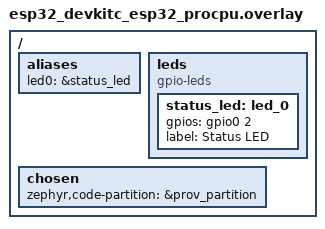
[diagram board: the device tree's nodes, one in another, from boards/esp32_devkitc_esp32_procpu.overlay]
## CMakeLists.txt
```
# SPDX-License-Identifier: Apache-2.0
#
# Wi-Fi provisioner: Improv Wi-Fi over BLE in its own image, launched by
# MCUboot from prov_partition. Built as an extra sysbuild image by each app's
# sysbuild.cmake (see sysbuild/provisioning.cmake); not built on its own.
cmake_minimum_required(VERSION 3.20.0)

list(APPEND ZEPHYR_EXTRA_MODULES
  ${CMAKE_CURRENT_SOURCE_DIR}/../../lib/common
)

find_package(Zephyr REQUIRED HINTS $ENV{ZEPHYR_BASE})
project(wifi_provisioner C)

target_sources(app PRIVATE src/main.c)
# Exactly one provisioning protocol (the APP_PROV_PROTOCOL choice).
if(CONFIG_APP_WIFI_PROV_SOFTAP)
  target_sources(app PRIVATE src/softap.c)
elseif(CONFIG_APP_PROV_ZTP)
  target_sources(app PRIVATE
    src/ztp.c
    src/ztp_envelope.c
    src/ztp_manifest.c
    src/ztp_apply.c
  )
else()
  target_sources(app PRIVATE src/improv.c)
endif()
target_sources_ifdef(CONFIG_APP_PROV_ZTP_CRYPTO app PRIVATE src/ztp_crypto.c)
target_sources_ifdef(CONFIG_APP_PROV_ZTP_CRYPTO_SELFTEST app PRIVATE src/ztp_selftest.c)
```

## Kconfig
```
# SPDX-License-Identifier: Apache-2.0
#
# Wi-Fi provisioner. Shared options come from the lib/common module.

mainmenu "Wi-Fi Provisioner"

menu "Wi-Fi provisioner"

config APP_WIFI_PROV_WINDOW_S
	int "Provisioning window (s)"
	default 900
	range 30 86400
	help
	  How long the provisioner advertises. When it expires and the
	  application still has credentials (entered with the button pattern),
	  it reboots back into the application; with no credentials it stops
	  advertising until sw0 is pressed.

config APP_WIFI_PROV_CONNECT_TIMEOUT_S
	int "Seconds to wait for an IPv4 address when testing credentials"
	default 30
	range 5 120

choice APP_PROV_PROTOCOL
	prompt "Provisioning protocol"
	default APP_PROV_IMPROV
	help
	  Exactly one protocol per image. Two 128-bit service UUIDs do not fit
	  one 31-byte advertising PDU, so a second BLE service would be
	  invisible to any client that scans by UUID; and the prov partition
	  has no room for both.

config APP_PROV_IMPROV
	bool "Improv Wi-Fi over BLE"
	help
	  Wi-Fi SSID and password only, from any stock Improv client.

config APP_PROV_ZTP
	bool "lab-ztp-provisioner over BLE (Wi-Fi and Cumulocity)"
	select APP_PROV_ZTP_CRYPTO
	help
	  The device is a peripheral for a lab-ztp-provisioner relay (the web
	  or desktop app on a phone or laptop), which forwards its signed
	  enrollment request to a ZTP server and writes the server's bundle
	  back. One session delivers Wi-Fi credentials and Cumulocity
	  onboarding: tenant, external ID and a one-time password the server
	  has already registered. The server profile must select
	  `crypto: {suite: p256}`.

config APP_WIFI_PROV_SOFTAP
	bool "SoftAP captive portal (spike)"
	depends on ESP32_WIFI_AP_STA_MODE
	help
	  c8y-direct-spikes, Spike E: an open access point "<hostname>-setup"
	  with DHCP, a catch-all DNS responder and an HTTP form, instead of
	  a BLE service. Use overlay-softap.conf and softap.overlay.

endchoice

config APP_WIFI_PROV_REQUIRE_AUTH
	bool "Require a sw0 press to authorize provisioning"
	depends on APP_PROV_IMPROV
	help
	  Start in the Improv "authorization required" state and refuse Wi-Fi
	  settings until sw0 is pressed on the device, which authorizes for 60 s.
	  Proves physical presence, since the link is not encrypted.

config APP_PROV_ZTP_CRYPTO
	bool
	help
	  The p256 crypto suite of the lab-ztp-provisioner protocol (ECDSA
	  P-256 / SHA-256 signatures; P-256 ECDH + HKDF-SHA256 +
	  ChaCha20-Poly1305 sealing), all over PSA. One curve only: Mbed TLS
	  has no Ed25519, and the prov partition has no room for a second.
	select MBEDTLS
	select MBEDTLS_PSA_CRYPTO_C
	select PSA_WANT_ECC_SECP_R1_256
	select PSA_WANT_KEY_TYPE_ECC_KEY_PAIR_BASIC
	select PSA_WANT_KEY_TYPE_ECC_KEY_PAIR_GENERATE
	select PSA_WANT_KEY_TYPE_ECC_KEY_PAIR_IMPORT
	select PSA_WANT_KEY_TYPE_ECC_KEY_PAIR_EXPORT
	select PSA_WANT_KEY_TYPE_ECC_PUBLIC_KEY
	select PSA_WANT_ALG_ECDSA
	select PSA_WANT_ALG_SHA_256
	select PSA_WANT_ALG_ECDH
	select PSA_WANT_ALG_HKDF
	select PSA_WANT_KEY_TYPE_DERIVE
	select PSA_WANT_KEY_TYPE_CHACHA20
	select PSA_WANT_ALG_CHACHA20_POLY1305
	# The identity key persists in PSA ITS; the board conf picks the
	# settings-backed ITS store, as the tedge profiles do.
	select SECURE_STORAGE
	select SETTINGS
	select BASE64

config APP_PROV_ZTP_PSA_KEY_ID
	hex "PSA key ID of the ZTP identity key"
	depends on APP_PROV_ZTP_CRYPTO
	default 0x0007E572
	range 0x00000001 0x3FFFFFFF
	help
	  Persistent key ID in PSA ITS. Distinct from CONFIG_TEDGE_PSA_KEY_ID
	  (the Cumulocity device key, 0x0007E571 by default): the two answer
	  to different trust roots, and re-provisioning must not replace the
	  key the device holds a Cumulocity certificate for.

if APP_PROV_ZTP

config APP_PROV_ZTP_RX_BYTES
	int "Largest server response the device accepts (bytes)"
	default 4096
	range 1024 16384
	help
	  Size of the buffer the relay writes the server's response into. The
	  device sends it to the server as max_response_bytes, so a bundle that
	  would not fit comes back as a rejection with a reason instead of a
	  truncated write. A Wi-Fi + Cumulocity bundle is about 2.5 KB.

config APP_PROV_ZTP_SERVER_PUBKEY
	string "Pinned ZTP server public key (base64, P-256)"
	default ""
	help
	  Reserved for verifying the server's signature on the bundle. Empty
	  (the only supported value for now) means trust on first use: the
	  bundle is applied unverified, with a warning. The sealed Cumulocity
	  token is protected either way; what TOFU leaves open is a hostile
	  relay choosing the Wi-Fi network and the tenant.

endif # APP_PROV_ZTP

config APP_PROV_ZTP_CRYPTO_SELFTEST
	bool "Run the ZTP p256 crypto self-test at boot"
	select APP_PROV_ZTP_CRYPTO
	help
	  Before provisioning starts, check every PSA operation the ZTP p256
	  suite needs against reference vectors from the lab-ztp-provisioner
	  Go implementation, and log PASS/FAIL with timings. For bring-up and
	  for new boards; see overlay-ztp-selftest.conf.

endmenu

source "Kconfig.zephyr"
```

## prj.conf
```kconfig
# SPDX-License-Identifier: Apache-2.0
#
# Wi-Fi provisioner: Improv Wi-Fi over BLE, Wi-Fi to test the credentials, and
# the credential store the application reads. No protocol frontend and no mDNS.
# The Wi-Fi driver itself is selected per board (boards/<board>.conf).

CONFIG_APP_FIRMWARE_NAME="wifi-provisioner"
CONFIG_APP_WIFI_PROVISIONER=y
CONFIG_APP_WIFI_CRED_STORE=y
# Waiting for credentials is "offline" by design: no last-resort reboot. The
# liveness watchdog stays (default on), so a wedged driver still resets the
# device, and the boot request brings it back here.
CONFIG_APP_NET_RECONNECT_REBOOT=n

# --- Bluetooth: one peripheral connection, no pairing ---
CONFIG_BT=y
CONFIG_BT_PERIPHERAL=y
CONFIG_BT_MAX_CONN=1
CONFIG_BT_MAX_PAIRED=0
CONFIG_BT_SMP=n
# The advertised name is the application's hostname, set at runtime.
CONFIG_BT_DEVICE_NAME_DYNAMIC=y
CONFIG_BT_DEVICE_NAME_MAX=32
# One Improv "send Wi-Fi settings" frame is at most 101 bytes. A larger ATT MTU
# lets it arrive in a single write; the prepare queue covers clients that use a
# long (queued) write instead.
CONFIG_BT_L2CAP_TX_MTU=247
CONFIG_BT_BUF_ACL_RX_SIZE=251
CONFIG_BT_BUF_ACL_TX_SIZE=251
CONFIG_BT_ATT_PREPARE_COUNT=2
# Wi-Fi/BLE software coexistence (ESP32_SW_COEXIST_ENABLE) defaults on once
# both radios are enabled; the credential test runs Wi-Fi while BLE is up.

# --- Networking: a station that can get a DHCP address, nothing more ---
CONFIG_NETWORKING=y
CONFIG_NET_L2_ETHERNET=y
CONFIG_NET_IPV4=y
CONFIG_NET_IPV6=n
CONFIG_NET_UDP=y
CONFIG_NET_TCP=n
CONFIG_NET_DHCPV4=y
CONFIG_NET_MGMT=y
CONFIG_NET_MGMT_EVENT=y
CONFIG_NET_MGMT_EVENT_INFO=y
CONFIG_NET_CONNECTION_MANAGER=y
# Fallback BLE name before any application has run: tedge-prov<mac>.
CONFIG_NET_HOSTNAME_ENABLE=y
CONFIG_NET_HOSTNAME="tedge-prov"
CONFIG_NET_HOSTNAME_UNIQUE=y

# --- Button (sw0) ---
CONFIG_GPIO=y
CONFIG_REBOOT=y

# --- Runtime / logging ---
CONFIG_LOG=y
# Warnings and errors only. The provisioner's logs serve provisioning alone,
# and its 1 MB prov partition was 96.8 % full on the ESP32-C6 with the ZTP
# overlay: level 2 drops the info strings and their call sites, and the
# flash-mapped code then ends before a 64 KB image boundary, which is where
# the size actually moves (scripts/release/size.py reports content and
# padding). The provisioning steps still report on the console at warning
# level where something goes wrong (reduce-memory-footprint, tier 3).
CONFIG_LOG_DEFAULT_LEVEL=2
# Minimal log mode (messages go straight to the console through printk: no
# deferred log core, packaging or UART backend, no timestamps) and the nano
# formatter, which does all the printing here. Together with level 2 they
# take 12.6 KB of content off the C6 ZTP provisioner and, decisively, move
# its flash-mapped code below a 64 KB image boundary: 1,015,243 -> 948,346 B
# (96.8 -> 90.4 % of prov, measured 2026-09-22). That code now ends 32 B
# before the boundary, so a few hundred bytes of growth put the image back
# at 96.7 %; the release size gate (92 % budget) is what catches it.
CONFIG_LOG_MODE_MINIMAL=y
CONFIG_CBPRINTF_NANO=y
# CBPRINTF_NANO also makes picolibc's printf family default to its minimal
# level, which ignores width and zero padding: snprintf("%02u") printed "9",
# the ZTP request timestamp came out as 2026-9-23T5:54:40Z and the server
# rejected it (found on the WROOM, 2026-09-23). The integer level formats
# width, padding and precision; only the logs use the nano formatter.
CONFIG_PICOLIBC_IO_INTEGER=y
CONFIG_MAIN_STACK_SIZE=4096
# The system heap is not set: the Wi-Fi and Bluetooth drivers' minimums win
# over any smaller value, and the provisioner resolves to 80,896 B on the
# ESP32 and ESP32-S3 and 105,296 B on the ESP32-C6 whatever is written here.
CONFIG_SYSTEM_WORKQUEUE_STACK_SIZE=2048
```

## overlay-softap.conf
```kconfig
# SPDX-License-Identifier: Apache-2.0
#
# Spike E (c8y-direct-spikes section 9): the provisioner with a SoftAP captive
# portal instead of Improv over BLE. Pass to the provisioner image with the
# devicetree overlay softap.overlay, e.g. in a sysbuild build of an app:
#   -Dwifi-provisioner_EXTRA_CONF_FILE=.../overlay-softap.conf
#   -Dwifi-provisioner_EXTRA_DTC_OVERLAY_FILE=.../softap.overlay

CONFIG_BT=n
CONFIG_APP_WIFI_PROV_SOFTAP=y

# AP + station at the same time (the station tests the credentials).
CONFIG_WIFI_NM=y
CONFIG_WIFI_USAGE_MODE_STA_AP=y
CONFIG_NET_L2_WIFI_MGMT=y
CONFIG_NET_IF_MAX_IPV4_COUNT=2

# DHCP server on the AP; the phone's DNS server is the device itself.
CONFIG_NET_DHCPV4_SERVER=y
CONFIG_NET_DHCPV4_SERVER_OPTION_DNS_ADDRESS="192.168.4.1"

# HTTP form.
CONFIG_NET_TCP=y
CONFIG_NET_SOCKETS=y
CONFIG_NET_MAX_CONN=6
CONFIG_ZVFS_OPEN_MAX=10
CONFIG_ZVFS_POLL_MAX=6
CONFIG_NET_PKT_RX_COUNT=16
CONFIG_NET_PKT_TX_COUNT=16
CONFIG_NET_BUF_RX_COUNT=32
CONFIG_NET_BUF_TX_COUNT=32
CONFIG_NET_MGMT_EVENT_STACK_SIZE=4096
CONFIG_NET_SOCKETS_SERVICE_STACK_SIZE=4096
CONFIG_MAIN_STACK_SIZE=6144
```

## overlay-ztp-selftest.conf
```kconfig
# SPDX-License-Identifier: Apache-2.0
#
# ZTP p256 crypto self-test at boot (ztp-ble-provisioner, spike tasks 1.1/1.3).
# Pass it to the provisioner image of a sysbuild build:
#
#   west build --sysbuild -b <board> apps/<app> -- \
#     -Dwifi-provisioner_EXTRA_CONF_FILE=$PWD/apps/wifi-provisioner/overlay-ztp-selftest.conf
#
# It links in the whole crypto stack the ZTP protocol needs, so the image size
# it produces is the honest cost of the suite, not a guess.

CONFIG_APP_PROV_ZTP_CRYPTO_SELFTEST=y

# The identity key persists in PSA ITS through settings, as in the tedge
# profiles.
CONFIG_SECURE_STORAGE_ITS_STORE_IMPLEMENTATION_SETTINGS=y

# No dedicated Mbed TLS heap: PSA allocates from the libc heap, as the
# Bluetooth host's own PSA use already does. A dedicated 8 KB heap cost the
# WROOM-32 8 KB of dram0, which is at 90% before ZTP.
```

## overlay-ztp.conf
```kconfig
# SPDX-License-Identifier: Apache-2.0
#
# Provision over the lab-ztp-provisioner BLE protocol instead of Improv:
# Wi-Fi credentials plus Cumulocity onboarding in one session. The server
# profile must select `crypto: {suite: p256}`. Pass it to the provisioner image
# of a sysbuild build:
#
#   west build --sysbuild -b <board> apps/<app> -- \
#     -Dwifi-provisioner_EXTRA_CONF_FILE=$PWD/apps/wifi-provisioner/overlay-ztp.conf

CONFIG_APP_PROV_ZTP=y

# The device's ZTP identity key persists in PSA ITS through settings, the same
# store the tedge profiles use for the Cumulocity key.
CONFIG_SECURE_STORAGE_ITS_STORE_IMPLEMENTATION_SETTINGS=y

# The ZTP crypto keeps its AES tables in flash: the TF-PSA-Crypto Kconfig
# already selects this for the provisioner (both options show as =y in its
# .config), stated here so the 1 MB prov partition does not silently regain
# 8 KB of .bss and 6 KB of flash if that default moves.
CONFIG_MBEDTLS_AES_ROM_TABLES=y
CONFIG_MBEDTLS_AES_FEWER_TABLES=y
```

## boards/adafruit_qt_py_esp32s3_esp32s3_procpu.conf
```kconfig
# SPDX-License-Identifier: Apache-2.0
# Adafruit QT Py ESP32-S3: Wi-Fi driver (the overlay enables the Wi-Fi node).
CONFIG_WIFI=y
CONFIG_WIFI_ESP32=y
CONFIG_APP_WIFI=y
```

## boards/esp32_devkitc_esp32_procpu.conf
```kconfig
# SPDX-License-Identifier: Apache-2.0
# ESP32-WROOM-32 DevKitC (classic ESP32): Wi-Fi driver.
CONFIG_WIFI=y
CONFIG_WIFI_ESP32=y
CONFIG_APP_WIFI=y

# --- .noinit in DRAM region 1 (SRAM1), also under MCUboot ---
# Simple boot puts .noinit (thread stacks, net buffers; ~68 KB here) in the
# SRAM1 region a second-stage bootloader would use. Zephyr turns that off for
# MCUboot builds, which moves it into region 0 and takes it out of the libc
# heap (70 KB → 3 KB for OPC-UA). .noinit is never loaded, so MCUboot is done
# with that RAM by the time the application uses it. Without it the provisioner
# (Bluetooth's ~55 KB link-time reserve plus the Wi-Fi and Bluetooth heap
# shares) does not link.
CONFIG_ESP32_REGION_1_NOINIT=y
```

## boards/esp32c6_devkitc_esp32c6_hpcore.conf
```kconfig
# SPDX-License-Identifier: Apache-2.0
# ESP32-C6: Wi-Fi driver (the board devicetree enables the Wi-Fi and BLE nodes).
CONFIG_WIFI=y
CONFIG_WIFI_ESP32=y
CONFIG_APP_WIFI=y
```

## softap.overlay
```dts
/* SPDX-License-Identifier: Apache-2.0
 *
 * Spike E: the second Wi-Fi interface (the access point) for AP+STA mode.
 * The ESP32 driver creates it from a second espressif,esp32-wifi node.
 */
/ {
	wifi_ap: wifi_ap {
		compatible = "espressif,esp32-wifi";
		status = "okay";
	};
};
```

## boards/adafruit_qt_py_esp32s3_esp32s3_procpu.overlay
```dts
/* SPDX-License-Identifier: Apache-2.0
 *
 * Adafruit QT Py ESP32-S3 (N4R2): the provisioner layout, linked for and
 * launched from prov_partition. The board devicetree leaves Wi-Fi disabled and
 * already puts the console on USB-Serial-JTAG.
 */
#include "../../../lib/common/dts/layout-esp32s3-4M.dtsi"

&wifi {
	status = "okay";
};

/ {
	chosen {
		zephyr,code-partition = &prov_partition;
	};
};
```

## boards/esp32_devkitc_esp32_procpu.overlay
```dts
/* SPDX-License-Identifier: Apache-2.0
 *
 * ESP32-WROOM-32 DevKitC (classic ESP32, 4 MB): the provisioner layout, linked
 * for and launched from prov_partition, and the status LED on GPIO2 that the
 * applications use, so the provisioning pattern shows.
 */
#include <zephyr/dt-bindings/gpio/gpio.h>
#include "../../../lib/common/dts/layout-esp32-4M.dtsi"

/ {
	aliases {
		led0 = &status_led;
	};

	leds {
		compatible = "gpio-leds";
		status_led: led_0 {
			gpios = <&gpio0 2 GPIO_ACTIVE_HIGH>;
			label = "Status LED";
		};
	};

	chosen {
		zephyr,code-partition = &prov_partition;
	};
};
```

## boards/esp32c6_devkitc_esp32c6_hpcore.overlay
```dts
/* SPDX-License-Identifier: Apache-2.0
 *
 * ESP32-C6 (ESP32-C6-WROOM-1-N4): the provisioner layout, linked for and
 * launched from prov_partition, with the console on USB-Serial-JTAG like the
 * applications (see apps/modbus-server/boards/ for the console notes).
 */
#include "../../../lib/common/dts/layout-esp32c6-4M.dtsi"

&usb_serial {
	status = "okay";
};

/ {
	chosen {
		zephyr,console = &usb_serial;
		zephyr,shell-uart = &usb_serial;
		zephyr,code-partition = &prov_partition;
	};
};

/* Status LED: the WS2812 RGB LED on GPIO8. */
#include "../../../lib/common/dts/rgb-led-esp32c6-gpio8.dtsi"
```

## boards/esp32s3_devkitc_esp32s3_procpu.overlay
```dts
/* SPDX-License-Identifier: Apache-2.0
 *
 * ESP32-S3-DevKitC-1 (N16R8): the provisioner layout, linked for and launched
 * from prov_partition. Console on uart0 like the applications.
 */
#include "../../../lib/common/dts/layout-esp32s3-16M.dtsi"

/ {
	chosen {
		zephyr,code-partition = &prov_partition;
	};
};

/* Status LED: the WS2812 RGB LED. */
#include "../../../lib/common/dts/rgb-led-esp32s3-devkitc.dtsi"
```

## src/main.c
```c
/* SPDX-License-Identifier: Apache-2.0
 *
 * Wi-Fi provisioner: a separate image in `prov_partition` that MCUboot
 * launches when the application has set the boot request (no credentials, or
 * the sw0 provisioning pattern). It advertises the Improv Wi-Fi BLE service
 * (or, with CONFIG_APP_WIFI_PROV_SOFTAP, a SoftAP captive portal),
 * tests the credentials a client sends by joining the network, stores them
 * for the application and reboots back into it. It carries Bluetooth so the
 * applications do not have to.
 */

#include <zephyr/kernel.h>
#include <zephyr/logging/log.h>

#if defined(CONFIG_APP_WIFI_PROV_SOFTAP)
#include "softap.h"
#elif defined(CONFIG_APP_PROV_ZTP)
#include "ztp.h"
#else
#include "improv.h"
#endif
#include "net.h"
#if defined(CONFIG_APP_PROV_ZTP_CRYPTO_SELFTEST)
#include "ztp_selftest.h"
#endif

LOG_MODULE_REGISTER(main, CONFIG_LOG_DEFAULT_LEVEL);

int main(void)
{
	LOG_INF("Wi-Fi provisioner starting");

#if defined(CONFIG_APP_PROV_ZTP_CRYPTO_SELFTEST)
	/* Diagnostic only: a failure is logged, provisioning still starts. */
	(void)ztp_selftest_run();
#endif

	int rc = app_net_init();

	if (rc) {
		LOG_ERR("Wi-Fi init failed (%d)", rc);
	}
#if defined(CONFIG_APP_WIFI_PROV_SOFTAP)
	softap_run();
#elif defined(CONFIG_APP_PROV_ZTP)
	ztp_run();
#else
	improv_run();
#endif
}
```

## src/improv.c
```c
/* SPDX-License-Identifier: Apache-2.0
 *
 * Improv Wi-Fi over BLE (https://www.improv-wifi.com/ble/): the GATT service
 * and the provisioning state machine of the Wi-Fi provisioner. Credentials are
 * only stored after the device has joined the network with them. Every exit
 * clears the boot request and reboots, so MCUboot runs the application next.
 */

#include "improv.h"
#include "boot_request.h"
#include "net.h"
#include "prov_identity.h"
#include "status_led.h"

#include <zephyr/kernel.h>
#include <zephyr/logging/log.h>
#include <zephyr/logging/log_ctrl.h>
#include <zephyr/sys/reboot.h>
#include <zephyr/drivers/gpio.h>
#include <zephyr/bluetooth/bluetooth.h>
#include <zephyr/bluetooth/conn.h>
#include <zephyr/bluetooth/gatt.h>
#include <zephyr/bluetooth/uuid.h>
#include <zephyr/net/wifi.h>
#include <zephyr/net/wifi_credentials.h>
#include <string.h>
#include <stdio.h>

LOG_MODULE_REGISTER(improv, CONFIG_LOG_DEFAULT_LEVEL);

#define AUTH_PERIOD_MS     60000 /* Improv convention: 1 minute */
#define IDENTIFY_MS        10000
#define RESULT_GRACE_MS    5000  /* time for the client to read the result */
#define BTN_DEBOUNCE_MS    30

/* ------------------------------------------------------------------------- */
/* Provisioning-mode events                                                  */
/* ------------------------------------------------------------------------- */

enum prov_msg_type {
	MSG_SETTINGS, /* Improv "send Wi-Fi settings" RPC */
	MSG_BUTTON,   /* sw0 pressed */
};

struct prov_msg {
	enum prov_msg_type type;
	struct app_wifi_creds creds;
};

K_MSGQ_DEFINE(prov_q, sizeof(struct prov_msg), 2, 4);

/* ------------------------------------------------------------------------- */
/* sw0: a short press restarts an expired window or authorizes              */
/* ------------------------------------------------------------------------- */

#if DT_NODE_HAS_STATUS(DT_ALIAS(sw0), okay)

static const struct gpio_dt_spec btn = GPIO_DT_SPEC_GET(DT_ALIAS(sw0), gpios);
static struct gpio_callback btn_cb;
static struct k_work_delayable btn_work;
static bool btn_level;

static void btn_isr(const struct device *dev, struct gpio_callback *cb,
		    uint32_t pins)
{
	ARG_UNUSED(dev);
	ARG_UNUSED(cb);
	ARG_UNUSED(pins);
	(void)k_work_reschedule_for_queue(app_net_workq(), &btn_work,
					  K_MSEC(BTN_DEBOUNCE_MS));
}

static void btn_work_fn(struct k_work *work)
{
	ARG_UNUSED(work);
	bool level = gpio_pin_get_dt(&btn) > 0;

	if (level != btn_level) {
		btn_level = level;
		if (level) {
			struct prov_msg m = { .type = MSG_BUTTON };

			(void)k_msgq_put(&prov_q, &m, K_NO_WAIT);
		}
	}
}

static void button_start(void)
{
	if (!gpio_is_ready_dt(&btn)) {
		return;
	}
	k_work_init_delayable(&btn_work, btn_work_fn);
	if (gpio_pin_configure_dt(&btn, GPIO_INPUT) != 0 ||
	    gpio_pin_interrupt_configure_dt(&btn, GPIO_INT_EDGE_BOTH) != 0) {
		LOG_ERR("sw0 configuration failed");
		return;
	}
	btn_level = gpio_pin_get_dt(&btn) > 0;
	gpio_init_callback(&btn_cb, btn_isr, BIT(btn.pin));
	(void)gpio_add_callback(btn.port, &btn_cb);
}

#else /* no sw0 on this board */

static void button_start(void)
{
}

#endif

/* ------------------------------------------------------------------------- */
/* Improv Wi-Fi GATT service                                                 */
/* ------------------------------------------------------------------------- */

#define IMPROV_UUID(n) \
	BT_UUID_128_ENCODE(0x00467768, 0x6228, 0x2272, 0x4663, 0x277478268000 + (n))

enum improv_state {
	ST_AUTH_REQUIRED = 0x01,
	ST_AUTHORIZED = 0x02,
	ST_PROVISIONING = 0x03,
	ST_PROVISIONED = 0x04,
};

enum improv_error {
	ERR_NONE = 0x00,
	ERR_INVALID_RPC = 0x01,
	ERR_UNKNOWN_RPC = 0x02,
	ERR_UNABLE_TO_CONNECT = 0x03,
	ERR_NOT_AUTHORIZED = 0x04,
	ERR_UNKNOWN = 0xFF,
};

enum improv_cmd {
	CMD_WIFI_SETTINGS = 0x01,
	CMD_IDENTIFY = 0x02,
};

#define CAP_IDENTIFY 0x01
#define FRAME_MAX    (3 + 1 + 32 + 1 + 64) /* cmd, len, csum + settings */

static const struct bt_uuid_128 uuid_svc = BT_UUID_INIT_128(IMPROV_UUID(0));
static const struct bt_uuid_128 uuid_state = BT_UUID_INIT_128(IMPROV_UUID(1));
static const struct bt_uuid_128 uuid_error = BT_UUID_INIT_128(IMPROV_UUID(2));
static const struct bt_uuid_128 uuid_rpc = BT_UUID_INIT_128(IMPROV_UUID(3));
static const struct bt_uuid_128 uuid_result = BT_UUID_INIT_128(IMPROV_UUID(4));
static const struct bt_uuid_128 uuid_caps = BT_UUID_INIT_128(IMPROV_UUID(5));

static uint8_t cur_state = ST_AUTHORIZED;
static uint8_t cur_error = ERR_NONE;
static uint8_t caps;
static uint8_t result_buf[FRAME_MAX + 64];
static uint16_t result_len;

static uint8_t rx_buf[FRAME_MAX];
static uint16_t rx_len;
static int64_t rx_last;

static ssize_t read_u8(struct bt_conn *conn, const struct bt_gatt_attr *attr,
		       void *buf, uint16_t len, uint16_t offset)
{
	return bt_gatt_attr_read(conn, attr, buf, len, offset, attr->user_data,
				 sizeof(uint8_t));
}

static ssize_t read_result(struct bt_conn *conn,
			   const struct bt_gatt_attr *attr, void *buf,
			   uint16_t len, uint16_t offset)
{
	return bt_gatt_attr_read(conn, attr, buf, len, offset, result_buf,
				 result_len);
}

static ssize_t write_rpc(struct bt_conn *conn, const struct bt_gatt_attr *attr,
			 const void *buf, uint16_t len, uint16_t offset,
			 uint8_t flags);

BT_GATT_SERVICE_DEFINE(improv_svc,
	BT_GATT_PRIMARY_SERVICE(&uuid_svc),
	BT_GATT_CHARACTERISTIC(&uuid_state.uuid,
			       BT_GATT_CHRC_READ | BT_GATT_CHRC_NOTIFY,
			       BT_GATT_PERM_READ, read_u8, NULL, &cur_state),
	BT_GATT_CCC(NULL, BT_GATT_PERM_READ | BT_GATT_PERM_WRITE),
	BT_GATT_CHARACTERISTIC(&uuid_error.uuid,
			       BT_GATT_CHRC_READ | BT_GATT_CHRC_NOTIFY,
			       BT_GATT_PERM_READ, read_u8, NULL, &cur_error),
	BT_GATT_CCC(NULL, BT_GATT_PERM_READ | BT_GATT_PERM_WRITE),
	BT_GATT_CHARACTERISTIC(&uuid_rpc.uuid,
			       BT_GATT_CHRC_WRITE | BT_GATT_CHRC_WRITE_WITHOUT_RESP,
			       BT_GATT_PERM_WRITE | BT_GATT_PERM_PREPARE_WRITE,
			       NULL, write_rpc, NULL),
	BT_GATT_CHARACTERISTIC(&uuid_result.uuid,
			       BT_GATT_CHRC_READ | BT_GATT_CHRC_NOTIFY,
			       BT_GATT_PERM_READ, read_result, NULL, NULL),
	BT_GATT_CCC(NULL, BT_GATT_PERM_READ | BT_GATT_PERM_WRITE),
	BT_GATT_CHARACTERISTIC(&uuid_caps.uuid, BT_GATT_CHRC_READ,
			       BT_GATT_PERM_READ, read_u8, NULL, &caps),
);

/* --- Advertising: service UUID + Improv service data; name in scan resp --- */

static uint8_t svc_data[8] = { 0x77, 0x46 }; /* UUID 0x4677, LE */
static const uint8_t ad_uuid[] = { IMPROV_UUID(0) };
static const struct bt_data ad[] = {
	BT_DATA_BYTES(BT_DATA_FLAGS, (BT_LE_AD_GENERAL | BT_LE_AD_NO_BREDR)),
	BT_DATA(BT_DATA_UUID128_ALL, ad_uuid, sizeof(ad_uuid)),
	BT_DATA(BT_DATA_SVC_DATA16, svc_data, sizeof(svc_data)),
};
static struct bt_data sd[1];

static bool adv_wanted;
static bool adv_running;
static struct bt_conn *cur_conn;
static K_SEM_DEFINE(disconnected_sem, 0, 1);

static void adv_refresh_data(void)
{
	svc_data[2] = cur_state;
	svc_data[3] = caps;
	if (adv_running) {
		(void)bt_le_adv_update_data(ad, ARRAY_SIZE(ad), sd, ARRAY_SIZE(sd));
	}
}

static void adv_start(void)
{
	if (!adv_wanted || adv_running || cur_conn != NULL) {
		return;
	}
	adv_refresh_data();
	int err = bt_le_adv_start(BT_LE_ADV_CONN_FAST_2, ad, ARRAY_SIZE(ad), sd,
				  ARRAY_SIZE(sd));

	if (err) {
		LOG_ERR("Advertising failed to start (%d)", err);
		return;
	}
	adv_running = true;
}

static void adv_stop(void)
{
	adv_wanted = false;
	if (adv_running) {
		(void)bt_le_adv_stop();
		adv_running = false;
	}
}

static void adv_restart_fn(struct k_work *work)
{
	ARG_UNUSED(work);
	adv_start();
}

static K_WORK_DEFINE(adv_restart_work, adv_restart_fn);

/* The credential test runs Wi-Fi association and DHCP while the BLE link is
 * up, and with software coexistence on a single radio the link can miss
 * events for a few seconds. With a central's usual ~2 s supervision timeout
 * the link then drops and the client never sees the result, so ask for 5 s.
 * The values stay within Apple's accessory limits (interval 30-60 ms, no
 * latency, timeout 2-6 s) so macOS and iOS centrals accept them. */
static const struct bt_le_conn_param conn_param =
	BT_LE_CONN_PARAM_INIT(24, 48, 0, 500);

static void conn_param_fn(struct k_work *work)
{
	ARG_UNUSED(work);
	if (cur_conn != NULL) {
		int err = bt_conn_le_param_update(cur_conn, &conn_param);

		if (err) {
			LOG_WRN("Connection parameter request failed (%d)", err);
		}
	}
}

static K_WORK_DELAYABLE_DEFINE(conn_param_work, conn_param_fn);

static void on_connected(struct bt_conn *conn, uint8_t err)
{
	if (err) {
		return;
	}
	adv_running = false; /* connectable advertising stops on connect */
	cur_conn = bt_conn_ref(conn);
	LOG_INF("Provisioning client connected");
	/* After service discovery has settled. */
	k_work_reschedule(&conn_param_work, K_MSEC(500));
}

static void on_le_param_updated(struct bt_conn *conn, uint16_t interval,
				uint16_t latency, uint16_t timeout)
{
	ARG_UNUSED(conn);
	LOG_INF("Connection parameters: interval %u.%02u ms, latency %u, "
		"timeout %u ms", interval * 5 / 4, (interval * 125) % 100,
		latency, timeout * 10);
}

static void on_disconnected(struct bt_conn *conn, uint8_t reason)
{
	LOG_INF("Provisioning client disconnected (0x%02x)", reason);
	if (cur_conn == conn) {
		bt_conn_unref(cur_conn);
		cur_conn = NULL;
	}
	rx_len = 0;
	k_sem_give(&disconnected_sem);
}

static void on_recycled(void)
{
	k_work_submit(&adv_restart_work);
}

BT_CONN_CB_DEFINE(prov_conn_cbs) = {
	.connected = on_connected,
	.disconnected = on_disconnected,
	.le_param_updated = on_le_param_updated,
	.recycled = on_recycled,
};

static void notify_u8(const struct bt_uuid *uuid, uint8_t v)
{
	const struct bt_gatt_attr *a =
		bt_gatt_find_by_uuid(improv_svc.attrs, improv_svc.attr_count, uuid);

	if (a != NULL && cur_conn != NULL) {
		(void)bt_gatt_notify(cur_conn, a, &v, sizeof(v));
	}
}

static void set_state(uint8_t s)
{
	cur_state = s;
	notify_u8(&uuid_state.uuid, s);
	adv_refresh_data();
}

static void set_error(uint8_t e)
{
	cur_error = e;
	notify_u8(&uuid_error.uuid, e);
}

static uint8_t checksum(const uint8_t *p, size_t n)
{
	uint32_t sum = 0;

	for (size_t i = 0; i < n; i++) {
		sum += p[i];
	}
	return (uint8_t)sum;
}

/* Validate and dispatch one complete RPC frame (BT RX context). */
static void handle_frame(const uint8_t *f, size_t n)
{
	uint8_t cmd = f[0];
	uint8_t len = f[1];
	const uint8_t *d = &f[2];

	if (n != (size_t)len + 3 || checksum(f, n - 1) != f[n - 1]) {
		LOG_WRN("Improv RPC rejected: bad length or checksum");
		set_error(ERR_INVALID_RPC);
		return;
	}

	switch (cmd) {
	case CMD_IDENTIFY:
		set_error(ERR_NONE);
		status_led_flash(STATUS_LED_IDENTIFY, IDENTIFY_MS);
		return;
	case CMD_WIFI_SETTINGS: {
		struct prov_msg m = { .type = MSG_SETTINGS };
		uint8_t ssid_len = len >= 1 ? d[0] : 0;
		uint8_t psk_len;

		if (len < 2 || ssid_len == 0 || ssid_len > 32 ||
		    (size_t)ssid_len + 2 > len) {
			set_error(ERR_INVALID_RPC);
			return;
		}
		psk_len = d[1 + ssid_len];
		if (psk_len > 64 || (size_t)ssid_len + psk_len + 2 != len) {
			set_error(ERR_INVALID_RPC);
			return;
		}
		if (cur_state == ST_AUTH_REQUIRED) {
			set_error(ERR_NOT_AUTHORIZED);
			return;
		}
		if (cur_state != ST_AUTHORIZED) {
			return; /* already testing or provisioned */
		}
		memcpy(m.creds.ssid, &d[1], ssid_len);
		m.creds.ssid_len = ssid_len;
		memcpy(m.creds.psk, &d[2 + ssid_len], psk_len);
		m.creds.psk_len = psk_len;
		set_error(ERR_NONE);
		/* Move to "provisioning" now so a repeated write is ignored. */
		set_state(ST_PROVISIONING);
		if (k_msgq_put(&prov_q, &m, K_NO_WAIT) != 0) {
			set_state(ST_AUTHORIZED);
			set_error(ERR_UNKNOWN);
		}
		memset(&m, 0, sizeof(m));
		return;
	}
	default:
		set_error(ERR_UNKNOWN_RPC);
		return;
	}
}

static ssize_t write_rpc(struct bt_conn *conn, const struct bt_gatt_attr *attr,
			 const void *buf, uint16_t len, uint16_t offset,
			 uint8_t flags)
{
	ARG_UNUSED(conn);
	ARG_UNUSED(attr);

	if (flags & BT_GATT_WRITE_FLAG_PREPARE) {
		return 0; /* queued write: the data arrives on execute */
	}

	int64_t now = k_uptime_get();

	if (offset == 0) {
		/* A new frame, unless this continues a frame that an earlier
		 * write left incomplete (a frame split across writes). */
		bool continuing = rx_len >= 2 && rx_len < rx_buf[1] + 3u &&
				  now - rx_last < 2000 &&
				  !(flags & BT_GATT_WRITE_FLAG_EXECUTE);

		if (!continuing) {
			rx_len = 0;
		}
	} else if (offset != rx_len) {
		return BT_GATT_ERR(BT_ATT_ERR_INVALID_OFFSET);
	}
	rx_last = now;

	if ((size_t)rx_len + len > sizeof(rx_buf)) {
		rx_len = 0;
		set_error(ERR_INVALID_RPC);
		return len;
	}
	memcpy(&rx_buf[rx_len], buf, len);
	rx_len += len;

	if (rx_len >= 2 && rx_len >= rx_buf[1] + 3u) {
		handle_frame(rx_buf, rx_len);
		memset(rx_buf, 0, sizeof(rx_buf));
		rx_len = 0;
	}
	return len;
}

/* ------------------------------------------------------------------------- */
/* Provisioning state machine                                                */
/* ------------------------------------------------------------------------- */

/* The application this provisioner hands back to (from its identity record);
 * has_ident is false before any application has run. */
static struct prov_identity ident;
static bool has_ident;

/* URL scheme for the RPC result, from the DNS-SD service type. */
static const char *url_scheme(const char *t)
{
	if (strcmp(t, "_opcua-tcp") == 0) {
		return "opc.tcp";
	}
	return (t[0] == '_') ? t + 1 : t;
}

/* Fill and notify the RPC result: the application's service URL, or an empty
 * URL list when no application identity is known yet. */
static void set_result_url(void)
{
	char url[80];
	int n = 0;

	if (has_ident) {
		n = snprintf(url, sizeof(url), "%s://%s.local:%u",
			     url_scheme(ident.service), ident.hostname,
			     ident.port);
		if (n < 0 || n >= (int)sizeof(url)) {
			n = 0;
		}
	}
	/* [cmd][len][str_len][str][checksum]; no strings when n is 0 */
	result_buf[0] = CMD_WIFI_SETTINGS;
	if (n > 0) {
		result_buf[1] = (uint8_t)(n + 1);
		result_buf[2] = (uint8_t)n;
		memcpy(&result_buf[3], url, n);
		result_len = 3 + n;
	} else {
		result_buf[1] = 0;
		result_len = 2;
	}
	result_buf[result_len] = checksum(result_buf, result_len);
	result_len++;

	const struct bt_gatt_attr *a = bt_gatt_find_by_uuid(
		improv_svc.attrs, improv_svc.attr_count, &uuid_result.uuid);

	if (a != NULL && cur_conn != NULL) {
		(void)bt_gatt_notify(cur_conn, a, result_buf, result_len);
	}
	LOG_INF("Provisioned%s%s", n ? ": " : "", n ? url : "");
}

static uint8_t idle_state(void)
{
	return IS_ENABLED(CONFIG_APP_WIFI_PROV_REQUIRE_AUTH) ? ST_AUTH_REQUIRED
							     : ST_AUTHORIZED;
}

/* Every exit: clear the boot request so MCUboot runs the application. */
static FUNC_NORETURN void reboot_now(void)
{
	int rc = boot_request_clear();

	if (rc != 0) {
		LOG_ERR("Could not clear the boot request (%d)", rc);
	}
	LOG_INF("Leaving the provisioner: rebooting into the application");
	log_flush(); /* deferred logging: print before the reset */
	boot_request_reboot();
	CODE_UNREACHABLE;
}

/* Test the credentials; on success store them and reboot. */
static void try_settings(struct app_wifi_creds *c, int64_t auth_until)
{
	LOG_INF("Testing credentials for SSID \"%s\"", c->ssid);
	int rc = app_net_try_credentials(
		c, K_SECONDS(CONFIG_APP_WIFI_PROV_CONNECT_TIMEOUT_S));

	if (rc != 0) {
		LOG_WRN("Could not join \"%s\" (%d); nothing stored", c->ssid, rc);
		set_error(ERR_UNABLE_TO_CONNECT);
		set_state((auth_until && k_uptime_get() < auth_until) ||
				  !IS_ENABLED(CONFIG_APP_WIFI_PROV_REQUIRE_AUTH)
			  ? ST_AUTHORIZED : ST_AUTH_REQUIRED);
		return;
	}

	(void)wifi_credentials_delete_all();
	rc = wifi_credentials_set_personal(
		c->ssid, c->ssid_len,
		c->psk_len ? WIFI_SECURITY_TYPE_PSK : WIFI_SECURITY_TYPE_NONE,
		NULL, 0, c->psk, c->psk_len, 0, 0, 0);
	if (rc != 0) {
		LOG_ERR("Storing the credentials failed (%d)", rc);
		set_error(ERR_UNKNOWN);
		set_state(idle_state());
		return;
	}

	adv_stop();
	set_state(ST_PROVISIONED);
	set_result_url();

	/* Give the client time to read the result, then start serving. */
	k_sem_reset(&disconnected_sem);
	if (cur_conn != NULL) {
		(void)k_sem_take(&disconnected_sem, K_MSEC(RESULT_GRACE_MS));
	}
	reboot_now();
}

FUNC_NORETURN void improv_run(void)
{
	char name[CONFIG_BT_DEVICE_NAME_MAX];
	int64_t deadline = k_uptime_get() + CONFIG_APP_WIFI_PROV_WINDOW_S * 1000LL;
	int64_t auth_until = 0;
	bool idle = false;
	struct boot_request req;
	/* Entered with the button pattern: the application still has working
	 * credentials, so the window's end returns to it. */
	bool return_on_expiry = boot_request_read(&req) == 0 &&
				req.reason == BOOT_REQUEST_OPERATOR;

	status_led_set_mode(STATUS_LED_PROVISIONING);
	button_start();

	caps = status_led_present() ? CAP_IDENTIFY : 0;
	cur_state = idle_state();
	has_ident = prov_identity_load(&ident) == 0;

	int err = bt_enable(NULL);

	if (err) {
		LOG_ERR("Bluetooth init failed (%d)", err);
		k_sleep(K_SECONDS(30));
		boot_request_reboot(); /* retry; the request stays set */
	}

	/* The BLE name is capped at CONFIG_BT_DEVICE_NAME_MAX - 1 characters. */
	snprintf(name, sizeof(name), "%.*s", (int)sizeof(name) - 1,
		 has_ident ? ident.hostname : app_net_hostname());
	(void)bt_set_name(name);
	sd[0] = (struct bt_data)BT_DATA(BT_DATA_NAME_COMPLETE, bt_get_name(),
					strlen(bt_get_name()));

	adv_wanted = true;
	adv_start();
	LOG_INF("Advertising Improv Wi-Fi as \"%s\" for %d s", name,
		CONFIG_APP_WIFI_PROV_WINDOW_S);

	for (;;) {
		int64_t now = k_uptime_get();
		int64_t wake = idle ? INT64_MAX : deadline;

		if (auth_until && auth_until < wake) {
			wake = auth_until;
		}

		struct prov_msg m;
		k_timeout_t to = (wake == INT64_MAX) ? K_FOREVER
			       : K_MSEC(MAX(wake - now, 0));

		if (k_msgq_get(&prov_q, &m, to) == 0) {
			if (m.type == MSG_SETTINGS && !idle) {
				try_settings(&m.creds, auth_until);
				memset(&m, 0, sizeof(m));
			} else if (m.type == MSG_BUTTON) {
				if (idle) {
					LOG_INF("Button: advertising again");
					idle = false;
					deadline = k_uptime_get() +
						   CONFIG_APP_WIFI_PROV_WINDOW_S * 1000LL;
					status_led_set_mode(STATUS_LED_PROVISIONING);
					adv_wanted = true;
					adv_start();
				} else if (cur_state == ST_AUTH_REQUIRED ||
					   (cur_state == ST_AUTHORIZED &&
					    IS_ENABLED(CONFIG_APP_WIFI_PROV_REQUIRE_AUTH))) {
					LOG_INF("Button: authorized for %d s",
						AUTH_PERIOD_MS / 1000);
					auth_until = k_uptime_get() + AUTH_PERIOD_MS;
					set_state(ST_AUTHORIZED);
				}
			}
			continue;
		}

		now = k_uptime_get();
		if (auth_until && now >= auth_until) {
			auth_until = 0;
			if (cur_state == ST_AUTHORIZED) {
				set_state(ST_AUTH_REQUIRED);
			}
		}
		if (!idle && now >= deadline) {
			struct app_wifi_creds c;
			bool have = return_on_expiry ||
				    app_wifi_creds_resolve(&c) == 0;

			memset(&c, 0, sizeof(c));
			if (have) {
				LOG_INF("Provisioning window expired; returning "
					"to the configured network");
				reboot_now();
			}
			LOG_INF("Provisioning window expired; idle until "
				"the button is pressed");
			adv_stop();
			if (cur_conn != NULL) {
				(void)bt_conn_disconnect(
					cur_conn, BT_HCI_ERR_REMOTE_USER_TERM_CONN);
			}
			status_led_set_mode(STATUS_LED_OFF);
			idle = true;
		}
	}
}
```

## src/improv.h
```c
/* SPDX-License-Identifier: Apache-2.0 */
#ifndef IMPROV_H_
#define IMPROV_H_

#include <zephyr/toolchain.h>

/** Advertise Improv Wi-Fi and provision. Never returns: every exit clears the
 *  boot request and reboots into the application. */
FUNC_NORETURN void improv_run(void);

#endif /* IMPROV_H_ */
```

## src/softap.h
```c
/* SPDX-License-Identifier: Apache-2.0 */
#ifndef SOFTAP_H_
#define SOFTAP_H_

#include <zephyr/toolchain.h>

/** Run the SoftAP / captive-portal front end; never returns. */
FUNC_NORETURN void softap_run(void);

#endif /* SOFTAP_H_ */
```

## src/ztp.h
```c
/* SPDX-License-Identifier: Apache-2.0 */

#ifndef ZTP_H_
#define ZTP_H_

#include <zephyr/toolchain.h>

/**
 * @brief Run the lab-ztp-provisioner BLE peripheral until the device is
 * provisioned, then reboot into the application. Does not return.
 */
FUNC_NORETURN void ztp_run(void);

#endif /* ZTP_H_ */
```

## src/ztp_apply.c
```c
/* SPDX-License-Identifier: Apache-2.0 */

#include "ztp_apply.h"
#include "ztp_crypto.h"
#include "ztp_manifest.h"

#include "net.h"
#include "prov_c8y.h"

#include <errno.h>
#include <string.h>

#include <zephyr/linker/section_tags.h>
#include <zephyr/logging/log.h>
#include <zephyr/net/wifi.h>
#include <zephyr/net/wifi_credentials.h>
#include <zephyr/sys/base64.h>
#include <zephyr/sys/util.h>

LOG_MODULE_REGISTER(ztp_apply, CONFIG_LOG_DEFAULT_LEVEL);

/* One module's payload, clear or unsealed. wifi.v2 and c8y.v2 INI bodies are a
 * few hundred bytes; 1 KB leaves room for several networks. */
#define PAYLOAD_MAX 1024
#define CT_MAX      (PAYLOAD_MAX + ZTP_SEAL_TAG_LEN)

/* ------------------------------------------------------------------------ */
/* INI                                                                       */
/* ------------------------------------------------------------------------ */

/* Calls @p fn for every key=value line, with the section it is in. The INI
 * bodies come from pkg/server/payload/ini.go: "[section]" headers, then
 * "key=value" lines, no quoting or comments. */
typedef int (*ini_fn)(struct ztp_slice section, bool new_section,
		      struct ztp_kv *kv, void *arg);

static int ini_walk(const char *buf, size_t len, ini_fn fn, void *arg)
{
	const char *cur = buf;
	const char *end = buf + len;
	struct ztp_slice section = { "", 0 };

	while (cur < end) {
		const char *nl = memchr(cur, '\n', end - cur);
		const char *stop = nl ? nl : end;
		const char *line = cur;

		cur = nl ? nl + 1 : end;
		if (stop > line && stop[-1] == '\r') {
			stop--;
		}
		if (stop > line && line[0] == '[' && stop[-1] == ']') {
			section = (struct ztp_slice){ line + 1, stop - line - 2 };
			int rc = fn(section, true, NULL, arg);

			if (rc) {
				return rc;
			}
			continue;
		}
		const char *eq = memchr(line, '=', stop - line);

		if (eq == NULL) {
			continue;
		}
		struct ztp_kv kv = {
			.key = { line, eq - line },
			.val = { eq + 1, stop - eq - 1 },
		};
		int rc = fn(section, false, &kv, arg);

		if (rc) {
			return rc;
		}
	}
	return 0;
}

/* Copy a value into a fixed buffer, refusing to truncate: a truncated SSID,
 * password or token is a wrong one, not a shorter one. */
static int copy_val(char *dst, size_t size, struct ztp_slice v)
{
	if (v.len >= size) {
		return -E2BIG;
	}
	memcpy(dst, v.p, v.len);
	dst[v.len] = '\0';
	return 0;
}

/* ------------------------------------------------------------------------ */
/* wifi.v2                                                                   */
/* ------------------------------------------------------------------------ */

struct wifi_candidate {
	struct app_wifi_creds creds;
	int priority;
	bool open;       /* key_mgmt=NONE */
	bool seen_ssid;
};

static struct {
	struct app_wifi_creds best;
	int best_priority;
	bool have;
	struct wifi_candidate cur;
	bool in_network;
} wifi;

static void wifi_reset(void)
{
	memset(&wifi, 0, sizeof(wifi));
}

/* Close the current [network] section: keep it if it beats the best so far.
 * The first network wins a priority tie, matching declaration order. */
static void wifi_close_section(void)
{
	struct wifi_candidate *c = &wifi.cur;

	if (wifi.in_network && c->seen_ssid &&
	    (!wifi.have || c->priority > wifi.best_priority)) {
		if (c->open) {
			c->creds.psk[0] = '\0';
			c->creds.psk_len = 0;
		}
		wifi.best = c->creds;
		wifi.best_priority = c->priority;
		wifi.have = true;
	}
	memset(c, 0, sizeof(*c));
	wifi.in_network = false;
}

static int wifi_ini(struct ztp_slice section, bool new_section,
		    struct ztp_kv *kv, void *arg)
{
	struct wifi_candidate *c = &wifi.cur;

	ARG_UNUSED(arg);
	if (new_section) {
		wifi_close_section();
		wifi.in_network = ztp_slice_eq(section, "network");
		return 0;
	}
	if (!wifi.in_network) {
		return 0;
	}
	if (ztp_slice_eq(kv->key, "ssid")) {
		if (kv->val.len == 0 || copy_val(c->creds.ssid,
						 sizeof(c->creds.ssid), kv->val)) {
			return -EINVAL;
		}
		c->creds.ssid_len = kv->val.len;
		c->seen_ssid = true;
	} else if (ztp_slice_eq(kv->key, "password")) {
		if (copy_val(c->creds.psk, sizeof(c->creds.psk), kv->val)) {
			return -EINVAL;
		}
		c->creds.psk_len = kv->val.len;
	} else if (ztp_slice_eq(kv->key, "key_mgmt")) {
		c->open = ztp_slice_eq(kv->val, "NONE");
	} else if (ztp_slice_eq(kv->key, "priority")) {
		int p = 0;
		bool neg = kv->val.len && kv->val.p[0] == '-';

		for (size_t i = neg; i < kv->val.len && i < 6; i++) {
			if (kv->val.p[i] < '0' || kv->val.p[i] > '9') {
				return -EINVAL;
			}
			p = p * 10 + (kv->val.p[i] - '0');
		}
		c->priority = neg ? -p : p;
	}
	/* hidden: joining by SSID works for hidden networks as well. */
	return 0;
}

static int wifi_stage(const uint8_t *p, size_t len)
{
	int rc;

	wifi_reset();
	rc = ini_walk((const char *)p, len, wifi_ini, NULL);
	wifi_close_section();
	if (rc) {
		return rc;
	}
	if (!wifi.have) {
		return -ENODATA;
	}
	LOG_INF("wifi.v2: network \"%s\"%s", wifi.best.ssid,
		wifi.best.psk_len ? "" : " (open)");
	return 0;
}

/* Test the credentials by joining, then store them — the same rule Improv
 * follows, so a wrong password never replaces working credentials. */
static int wifi_commit(void)
{
	int rc;

	LOG_INF("Testing credentials for SSID \"%s\"", wifi.best.ssid);
	rc = app_net_try_credentials(
		&wifi.best, K_SECONDS(CONFIG_APP_WIFI_PROV_CONNECT_TIMEOUT_S));
	if (rc != 0) {
		LOG_WRN("Could not join \"%s\" (%d); nothing stored",
			wifi.best.ssid, rc);
		return -ENETUNREACH;
	}
	(void)wifi_credentials_delete_all();
	rc = wifi_credentials_set_personal(
		wifi.best.ssid, wifi.best.ssid_len,
		wifi.best.psk_len ? WIFI_SECURITY_TYPE_PSK : WIFI_SECURITY_TYPE_NONE,
		NULL, 0, wifi.best.psk, wifi.best.psk_len, 0, 0, 0);
	if (rc != 0) {
		LOG_ERR("Storing the credentials failed (%d)", rc);
	}
	return rc;
}

/* ------------------------------------------------------------------------ */
/* c8y.v2                                                                    */
/* ------------------------------------------------------------------------ */

static struct prov_c8y c8y;

static void c8y_reset(void)
{
	memset(&c8y, 0, sizeof(c8y)); /* also scrubs the one-time password */
}

static int c8y_ini(struct ztp_slice section, bool new_section,
		   struct ztp_kv *kv, void *arg)
{
	ARG_UNUSED(arg);
	if (new_section || !ztp_slice_eq(section, "c8y")) {
		return 0;
	}
	if (ztp_slice_eq(kv->key, "url")) {
		return copy_val(c8y.url, sizeof(c8y.url), kv->val);
	}
	if (ztp_slice_eq(kv->key, "tenant")) {
		return copy_val(c8y.tenant, sizeof(c8y.tenant), kv->val);
	}
	if (ztp_slice_eq(kv->key, "external_id")) {
		return copy_val(c8y.external_id, sizeof(c8y.external_id), kv->val);
	}
	if (ztp_slice_eq(kv->key, "one_time_password")) {
		return copy_val(c8y.otp, sizeof(c8y.otp), kv->val);
	}
	return 0;
}

static int c8y_stage(const uint8_t *p, size_t len)
{
	int rc;

	c8y_reset();
	rc = ini_walk((const char *)p, len, c8y_ini, NULL);
	if (rc) {
		c8y_reset();
		return rc;
	}
	if (c8y.url[0] == '\0') {
		return -ENODATA;
	}
	/* Never log the one-time password, only whether there is one. */
	LOG_INF("c8y.v2: %s, external ID \"%s\", %s", c8y.url,
		c8y.external_id[0] ? c8y.external_id : "(device default)",
		c8y.otp[0] ? "one-time password issued"
			   : "no one-time password (device generates one)");
	return 0;
}

static int c8y_commit(void)
{
	int rc = prov_c8y_store(&c8y);

	if (rc) {
		LOG_ERR("Storing the Cumulocity settings failed (%d)", rc);
	}
	c8y_reset();
	return rc;
}

/* ------------------------------------------------------------------------ */
/* Dispatch                                                                  */
/* ------------------------------------------------------------------------ */

struct ztp_applier {
	const char *type;
	int (*stage)(const uint8_t *payload, size_t len);
	int (*commit)(void);
	void (*reset)(void);
};

/* Commit order is table order: Wi-Fi must be proven before anything that
 * depends on the device being online is kept. */
static const struct ztp_applier appliers[] = {
	{ "wifi.v2", wifi_stage, wifi_commit, wifi_reset },
	{ "c8y.v2", c8y_stage, c8y_commit, c8y_reset },
};

/* __noinit: see the buffer note in ztp.c. */
static __noinit uint8_t payload[PAYLOAD_MAX];
static __noinit uint8_t ct[CT_MAX];

static int b64_exact(struct ztp_slice s, uint8_t *dst, size_t want)
{
	size_t olen;

	if (base64_decode(dst, want, &olen, (const uint8_t *)s.p, s.len) != 0 ||
	    olen != want) {
		return -EPROTO;
	}
	return 0;
}

/* Decode (and for a sealed module, open) a module into `payload`. */
static int module_payload(const struct ztp_module *m, size_t *len)
{
	size_t olen;

	if (!m->sealed) {
		if (base64_decode(payload, sizeof(payload), &olen,
				  (const uint8_t *)m->payload.p,
				  m->payload.len) != 0) {
			return -EPROTO;
		}
		*len = olen;
		return 0;
	}

	uint8_t eph[ZTP_P256_POINT_LEN];
	uint8_t nonce[ZTP_SEAL_NONCE_LEN];
	int rc;

	if (!ztp_slice_eq(m->format, "raw")) {
		return -ENOTSUP; /* both appliers take INI bodies */
	}
	if (b64_exact(m->eph, eph, sizeof(eph)) ||
	    b64_exact(m->nonce, nonce, sizeof(nonce)) ||
	    base64_decode(ct, sizeof(ct), &olen, (const uint8_t *)m->ciphertext.p,
			  m->ciphertext.len) != 0) {
		return -EPROTO;
	}
	rc = ztp_open(eph, nonce, ct, olen, payload, sizeof(payload), len);
	memset(ct, 0, sizeof(ct));
	return rc;
}

static const struct ztp_applier *find_applier(struct ztp_slice type)
{
	for (size_t i = 0; i < ARRAY_SIZE(appliers); i++) {
		if (ztp_slice_eq(type, appliers[i].type)) {
			return &appliers[i];
		}
	}
	return NULL;
}

static void reset_all(void)
{
	for (size_t i = 0; i < ARRAY_SIZE(appliers); i++) {
		appliers[i].reset();
	}
	memset(payload, 0, sizeof(payload));
}

int ztp_apply_manifest(const char *manifest, size_t len, const char *device_id)
{
	struct ztp_manifest_hdr hdr;
	struct ztp_module m;
	const char *cur = manifest;
	const char *end = manifest + len;
	bool staged[ARRAY_SIZE(appliers)] = { false };
	bool any = false;
	int rc;

	ztp_manifest_header(manifest, len, &hdr);
	if (!hdr.version_ok) {
		LOG_ERR("manifest: unsupported protocol version");
		return -EPROTO;
	}
	if (!ztp_slice_eq(hdr.device_id, device_id)) {
		/* A clear module (Wi-Fi) for another device must not be
		 * applied here; sealed ones would fail to open anyway. */
		LOG_ERR("manifest is for \"%.*s\", not \"%s\"",
			(int)hdr.device_id.len, hdr.device_id.p, device_id);
		return -EPROTO;
	}

	/* Phase 1: stage every module. Nothing is written yet. */
	reset_all();
	while ((rc = ztp_manifest_next_module(&cur, end, &m)) == 1) {
		const struct ztp_applier *a = find_applier(m.type);
		size_t plen;

		if (a == NULL) {
			LOG_INF("module %.*s: skipped (no applier)",
				(int)m.type.len, m.type.p);
			continue;
		}
		rc = module_payload(&m, &plen);
		if (rc == 0) {
			rc = a->stage(payload, plen);
		}
		memset(payload, 0, sizeof(payload));
		if (rc) {
			LOG_ERR("module %s: %s (%d)", a->type,
				rc == -EBADMSG ? "sealed payload did not open"
					       : "invalid",
				rc);
			reset_all();
			return rc;
		}
		staged[a - appliers] = true;
		any = true;
	}
	if (rc < 0) {
		LOG_ERR("manifest: malformed module line");
		reset_all();
		return rc;
	}
	if (!any) {
		LOG_ERR("bundle carries no module this device can apply");
		return -ENODATA;
	}

	/* Phase 2: commit in table order; stop at the first failure. */
	for (size_t i = 0; i < ARRAY_SIZE(appliers); i++) {
		if (!staged[i]) {
			continue;
		}
		rc = appliers[i].commit();
		if (rc) {
			reset_all();
			return rc;
		}
	}
	reset_all();
	return 0;
}
```
